# cmem7 register map
File version: 1.0
Registers are 32-bit, read-write, reset 0x0 unless marked. A register's access mark holds for its fields unless they carry their own. Offsets are from the block's base; [hi:lo] are bit positions; {n}, {i} and the like mark numbered series; 'fields as' and 'values as' point back to an identical list.

## CAN0
Base 0x41009000
Same registers: CAN1 0x4100D000
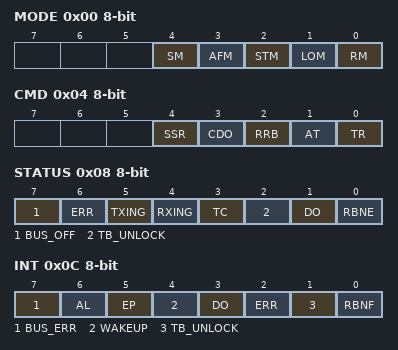
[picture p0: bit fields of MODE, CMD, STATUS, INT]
0x00 MODE 8-bit
  [4] SM — sleep mode
  [3] AFM — acceptance filter mode. Single filter if 1, dual filter if 0
  [2] STM — self test mode
  [1] LOM — Listen only mode
  [0] RM — reset mode if 1 or operation mode
0x04 CMD 8-bit wo — command Register
  [4] SSR — Set to 1 when a message is to be transmitted and received simultaneously
  [3] CDO — Set to 1 to clear the data overrun condition signaled by the Data Overrun Status bit (SR.1).
  [2] RRB — Set to 1 to release the Receive Buffer
  [1] AT — Set to 1 to cancel the next transmission request
  [0] TR — Set to 1 when a message is to be transmitted
0x08 STATUS 8-bit ro
  [7] BUS_OFF — in 'Bus Off' state
  [6] ERR — At least one of the error counters is more than Error Warning Limit Register
  [5] TXING — transmitting the data
  [4] RXING — receiving the data
  [3] TC — Transmission complete
  [2] TB_UNLOCK — Transmit Buffer is unlocked and not in transmitting
  [1] DO — Data Overrun Status
  [0] RBNE — Receive Buffer not empty
0x0C INT 8-bit ro — interrupt Register
  [7] BUS_ERR — Set when the MCAN2 detects an error on the CAN-bus
  [6] AL — Set when the MCAN2 loses arbitration and becomes a receiver
  [5] EP — Set when the MCAN2 re-enters error active state after being in error passive state or when at least one error counter exceeds the protocol-defined level of 127
  [4] WAKEUP
  [3] DO — Data Overrun Status
  [2] ERR — Set on every change (set or clear) of either the Bus Status or Error Status bits (SR.7,SR.6)
  [1] TB_UNLOCK — Transmit Buffer is unlocked and not in transmitting
  [0] RBNF — Receive Buffer not empty
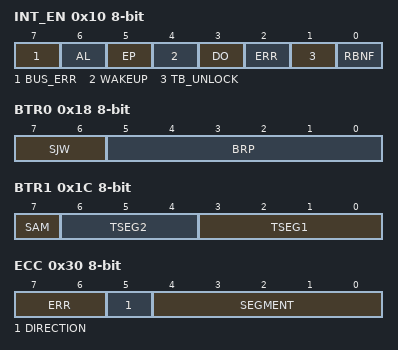
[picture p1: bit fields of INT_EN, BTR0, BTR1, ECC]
0x10 INT_EN 8-bit — interrupt enabled Register
  fields as INT
0x18 BTR0 8-bit — Bus Timing 0
  [7:6] SJW — the maximum number of time quanta of sync segment
  [5:0] BRP — TQ =2 x Txtal1 x (32 x BRP.5 + 16 x BRP.4 + 8 x BRP.3 + 4 x BRP.2 + 2 x BRP.1 + BRP.0 + 1)
0x1C BTR1 8-bit — Bus Timing 1
  [7] SAM — sample times. Sample 3 times if 1, once if 0
  [6:4] TSEG2 — the maximum number of time quanta of 2nd phase segment
  [3:0] TSEG1 — the maximum number of time quanta of propagation and 1st phase segment
0x20 OCR 8-bit — Output Control Register
  [1:0] MODE — output control mode
    2=OCR_MODE_NORMAL (TXD is sent to TX0 with the inverse sent to TX1); 3=OCR_MODE_CLOCK (TXD is sent to TX0 and TXCLK is sent to TX1)
0x2C ALC 8-bit ro — Arbitration Lost Capture
  [4:0] BIT — the current position of the Bit Processor when bus arbitration lost, 1st bit (ID.28) if 0
0x30 ECC 8-bit ro — Error Code Capture
  [7:6] ERR — error code
    0=ECC_ERR_BIT (bit error); 1=ECC_ERR_FORM (Form error); 2=ECC_ERR_STUFF (stuff error); 3=ECC_ERR_OTHER (Some other type of error)
  [5] DIRECTION — If 1, the error occurred during reception. If 0, the error occurred during transmission
  [4:0] SEGMENT — segment code
    2=ECC_SEGMENT_ID28_ID21 (ID.28 to ID.21); 3=ECC_SEGMENT_START_FRAME (start of frame); 4=ECC_SEGMENT_SRTR (SRTR bit); 5=ECC_SEGMENT_IDE (IDE bit); 6=ECC_SEGMENT_ID20_ID18 (ID.20 to ID.18); 7=ECC_SEGMENT_ID17_ID13 (ID.17 to ID.13); 8=ECC_SEGMENT_CRC_SEQUENCE (CRC sequence); 9=ECC_SEGMENT_RESERVED_0 (Reserved bit 0); 10=ECC_SEGMENT_DATA_FIELD (Data Field); 11=ECC_SEGMENT_DATA_LENGTH (Data length); 12=ECC_SEGMENT_RTR (RTR); 13=ECC_SEGMENT_RESERVED_1 (Reserved bit 1); 14=ECC_SEGMENT_ID4_ID0 (ID.4 to ID.0); 15=ECC_SEGMENT_ID12_ID5 (ID.12 to ID.5); 17=ECC_SEGMENT_ACTIVE_ERR_FLAG (Active error flag); 18=ECC_SEGMENT_INTERMISSION (Intermission); 19=ECC_SEGMENT_TOLERATE_DOMINANT_BITS (Tolerate dominant bits); 22=ECC_SEGMENT_PASSIVE_ERR_FLAG (Passive error flag); 23=ECC_SEGMENT_ERR_DELIMITER (Error delimiter); 24=ECC_SEGMENT_CRC_DELIMITER (CRC delimiter); 25=ECC_SEGMENT_ACK (Acknowledge); 26=ECC_SEGMENT_END_FRAME (End of frame); 27=ECC_SEGMENT_ACK_DELIMITER (Acknowledge delimiter); 28=ECC_SEGMENT_OVERLOAD_FLAG (Overload flag)
0x34 EWLR 8-bit — Error Warning Limit
0x38 RXERR 8-bit — Receive Error Counter
0x3C TXERR 8-bit — Transmit Error Counter
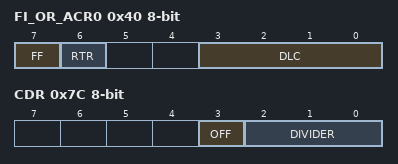
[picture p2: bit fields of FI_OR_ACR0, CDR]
0x40 FI_OR_ACR0 8-bit — Transmit Frame Information if writting or Receive Frame Information if reading, ACR[0] if reset mode
  [7] FF — 1 selects Extended Frame Format (EFF); 0 selects Standard Frame Format (SFF)
  [6] RTR — 1 indicates a remote frame; 0 indicates a data frame
  [3:0] DLC — byte number in the data
{0x44+4i} DI{i}_OR_ACR{i+1} 8-bit (i=0..2) — Transmit data Information if writting or Receive data Information if reading, ACR[{i+1}] if reset mode
{0x44+4i} DI{i}_OR_AMR{i-3} 8-bit (i=3..6) — Transmit data Information if writting or Receive data Information if reading, AMR[{i-3}] if reset mode
{0x44+4i} DI{i} (i=7..11) 8-bit — Transmit data Information if writting or Receive data Information if reading
0x74 RMC 8-bit — Receive Message Counter
0x7C CDR 8-bit — Clock Divider Register
  [3] OFF — disable XTAL1
  [2:0] DIVIDER — divider of XTAL1
    0=CDR_DIV_1_2 (1/2 XTAL1); 1=CDR_DIV_1_4 (1/4 XTAL1); 2=CDR_DIV_1_6 (1/6 XTAL1); 3=CDR_DIV_1_8 (1/8 XTAL1); 4=CDR_DIV_1_10 (1/10 XTAL1); 5=CDR_DIV_1_12 (1/12 XTAL1); 6=CDR_DIV_1_14 (1/14 XTAL1); 7=CDR_DIV_1_1 (XTAL1)
